# ZB32L030 register map
Vendor: ZBit.; Series: ZB32L03X; File version: 1.0
CPU: CM0+ r1p0, little endian, no MPU, no FPU, VTOR, 2 interrupt priority bits
Registers are 32-bit, read-write, reset 0x0 unless marked. A register's access mark holds for its fields unless they carry their own. Offsets are from the block's base; [hi:lo] are bit positions; {n}, {i} and the like mark numbered series.

## IWDG — Independ Watch Dog
Base 0x40002400
0x00 CMDCR — IWDG Control Command Register
  [7:0] CMD wo — Command
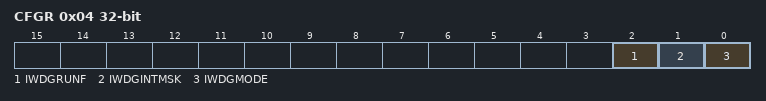
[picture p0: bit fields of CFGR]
0x04 CFGR — IWDG Config Register
  [2] IWDGRUNF ro — IWDG running flag
  [1] IWDGINTMSK — IWDG interrupt mask
  [0] IWDGMODE
0x08 RLOAD reset 0xFFFFF — Count ReLoad Register
  [19:0] IWDGRLOAD — IWDG reload value
0x0C CNTVAL reset 0xFFFFF — Count Value
  [19:0] IWDGCNT ro — IWDG count
0x10 SR — IWDG Interrupt Status Register
  [0] IWDGOVF ro — IWDG overflow flag
0x14 INTCLR — IWDG Interrupt Clear Register
  [0] IWDGINTCLR wo — IWDG interrupt clear
0x18 UNLOCK — IWDG register Writer Protect
  [0] IWDGREN — Set UNLOCK = 0x55AA6699 to unlock register

## BEEP
Base 0x40004800
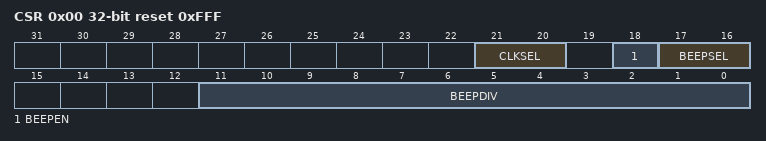
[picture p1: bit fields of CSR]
0x00 CSR reset 0xFFF — BEEP Control Status Register
  [21:20] CLKSEL — Clock select
    0=STOP (clock stop); 1=SIRC (clock use SIRC); 2=HXT (clock use HXT); 3=PCLK (clock use PCLK)
  [18] BEEPEN — BEEP Enable
  [17:16] BEEPSEL — BEEP clock select
    0=div8 (divide 8); 1=div4 (divide 4); 2=div2 (divide 2)
  [11:0] BEEPDIV — BEEP division

## AWK — Auto wake
Base 0x40002800
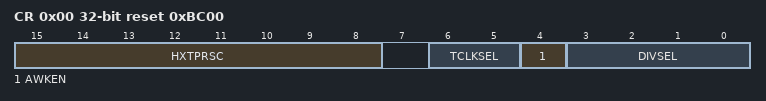
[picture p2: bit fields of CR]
0x00 CR reset 0xBC00 — Auto Wake Timer Control Register
  [15:8] HXTPRSC — HXT prescale
  [6:5] TCLKSEL — Clock select
    0=STOP; 1=SIRC (SIRC clock); 2=HXT (External high speed clock); 3=LXT (External low speed clock)
  [4] AWKEN — AWK Enable
  [3:0] DIVSEL — Division select
    0=DIV2 (divide by 2); 1=DIV4 (divide by 4); 2=DIV8 (divide by 8); 3=DIV16 (divide by 16); 4=DIV32 (divide by 32); 5=DIV64 (divide by 64); 6=DIV128 (divide by 128); 7=DIV256 (divide by 256); 8=DIV512 (divide by 512); 9=DIV1024 (divide by 1024); 10=DIV2048 (divide by 2048); 11=DIV4096 (divide by 4096); 12=DIV8192 (divide by 8192); 13=DIV16384 (divide by 16384); 14=DIV32768 (divide by 32768); 15=DIV65536 (divide by 65536)
0x04 RLOAD — Auto Wake Timer ReLoad Data Register
  [7:0] RLDVAL — Reload value
0x08 SR — Auto Wake Timer Status Register
  [0] AWUF ro — Auto wake-up flag
0x0C INTCLR — Auto Wake Interrupt Clear Register
  [0] INTCLR wo — interrupt flag clear

## LPTIM — Low Power Timer
Base 0x40004400
0x00 CNTVAL — Low Power Count Read_Only Register
  [15:0] LPT_CNT ro
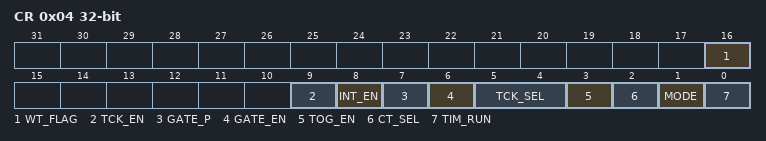
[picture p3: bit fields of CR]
0x04 CR — LPTIM Control Register
  [16] WT_FLAG ro
  [9] TCK_EN
  [8] INT_EN
  [7] GATE_P
  [6] GATE_EN
  [5:4] TCK_SEL
    0=PCLK (use PCLK); 2=LXT (use LXT); 3=SIRC (use SIRC)
  [3] TOG_EN
  [2] CT_SEL
  [1] MODE
  [0] TIM_RUN
0x08 LOAD — LPTIM Reload Register
  [15:0] LOAD
0x0C INTSR — LPTIM Interrupt Status
  [0] INTF ro — interrupt flag
0x10 INTCLR — LPTIM Interrupt Clear Register
  [0] ICLR wo
0x14 BGLOAD — LPTIM Circle reload Register
  [15:0] BGLOAD

## BASETIM — BASE TIMER
Base 0x40001800
Same registers: TIM10 0x40001800, TIM11 0x40001900
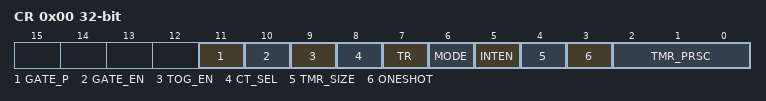
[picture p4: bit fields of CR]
0x00 CR — TIM10 Control Register
  [11] GATE_P
  [10] GATE_EN
  [9] TOG_EN
  [8] CT_SEL
  [7] TR
  [6] MODE
  [5] INTEN
  [4] TMR_SIZE
  [3] ONESHOT
  [2:0] TMR_PRSC
    0=DIV1 (division by 1); 1=DIV2 (division by 2); 2=DIV4 (division by 4); 3=DIV8 (division by 8); 4=DIV16 (division by 16); 5=DIV32 (division by 32); 6=DIV64 (division by 64); 7=DIV128 (division by 128)
0x04 LOAD — 32bits Auto Load Register
0x08 CNT — Read Count Register，Only Read
  [31:0] CNT ro
0x0C RAWINTSR
  [0] RIS ro
0x10 MSKINTSR — Read Interrupt Register
  [0] TF ro
0x14 INTCLR — Interrupt Clear Register
  [0] INTCLR wo
0x18 BGLOAD — 32Bits Circles Reload Register

## PCA — Programmable Counter Array
Base 0x40001400
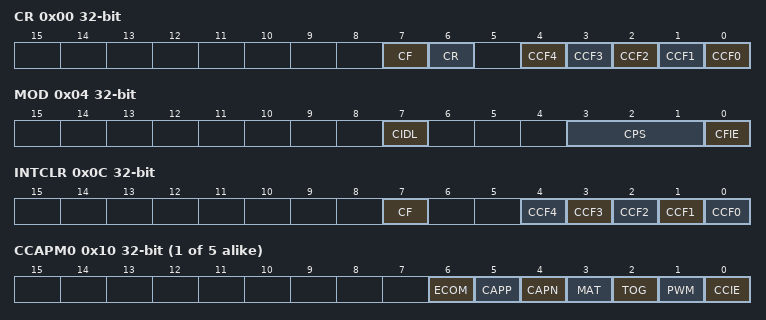
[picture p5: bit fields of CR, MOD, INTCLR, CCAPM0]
0x00 CR — Control Register
  [7] CF ro, [6] CR, [n] CCF{n} ro (n=0..4)
0x04 MOD — Mode Register
  [7] CIDL
  [3:1] CPS
    0=DIV32 (PCLK divide by 32); 1=DIV16 (PCLK divide by 16); 2=DIV8 (PCLK divide by 8); 3=DIV4 (PCLK divide by 4); 4=DIV2 (PCLK divide by 2); 5=TIM10_OVERFLOW (Timer10 overflow); 6=TIM11_OVERFLOW (Timer11 overflow); 7=ECI (External clock)
  [0] CFIE
0x08 CNT — PCA Count Register
  [15:0] CNT — PCA counter value
0x0C INTCLR — PCA Interrupt Clear Register
  [7] CF wo, [n] CCF{n} wo (n=0..4)
{0x10+4i} CCAPM{i} (i=0..4) — PCA Captuer/Compare Model {i} Mode Register
  [6] ECOM, [5] CAPP, [4] CAPN, [3] MAT, [2] TOG, [1] PWM, [0] CCIE
0x30 CCAP0L — PCA Capture/Compare Model0 Low 8 bits Register
  [7:0] CCAP0
0x34 CCAP0H — PCA Capture/Compare Model0 High 8 bits Register
  [7:0] CCAP0
0x38 CCAP1L — PCA Capture/Compare Model 1 Low 8 bits Register
  [7:0] CCAP1
{0x34+8i} CCAP{i}H (i=1..4) — PCA Capture/Compare Model {i} High 8 bits Register
  [7:0] CCAP{i}
0x40 CCAP2L reset 0xFFF — PCA Capture/Compare Model 2 Low 8 bits Register
  [7:0] CCAP2 ro
0x48 CCAP3L — PCA Capture/Compare Model 3 Low 8 bits Register
  [7:0] CCAP3
0x50 CCAP4L — PCA Capture/Compare Model 4 Low 8 bits Register
  [7:0] CCAP4
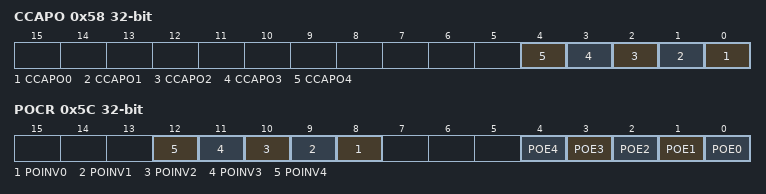
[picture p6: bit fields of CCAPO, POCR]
0x58 CCAPO — PCA EndPoint Output Flag Register
  [n] CCAPO{n} (n=0..4)
0x5C POCR — PCA EndPoint Output Control Register
  [n+8] POINV{n} (n=0..4), [n] POE{n} (n=0..4)
0x60 CCAP0 — PCA Capture/Compare Model0 16 bits Register
  [15:0] CCAP0
{0x60+4i} CCAP{i} (i=1..4) — PCA Capture/Compare Model {i} 16 bits Register
  [15:0] CCAP{i}
